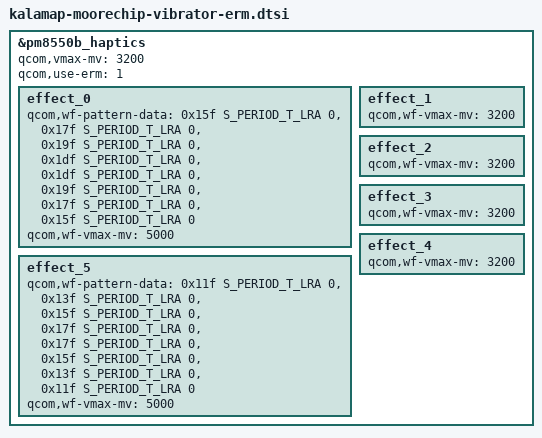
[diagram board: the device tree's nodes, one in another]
&pm8550b_haptics {
	status = "okay";
	qcom,vmax-mv = <3200>;
	qcom,use-erm = <1>;

	effect_0 {
		/* CLICK */
		qcom,wf-pattern-data =  <0x15f  S_PERIOD_T_LRA  0>,
					<0x17f  S_PERIOD_T_LRA  0>,
					<0x19f  S_PERIOD_T_LRA  0>,
					<0x1df  S_PERIOD_T_LRA  0>,
					<0x1df  S_PERIOD_T_LRA  0>,
					<0x19f  S_PERIOD_T_LRA  0>,
					<0x17f  S_PERIOD_T_LRA  0>,
					<0x15f  S_PERIOD_T_LRA  0>;
		/delete-property/ qcom,wf-pattern-preload;
		qcom,wf-vmax-mv = <5000>;
	};

	effect_1 {
		/* DOUBLE_CLICK */
		qcom,wf-vmax-mv = <3200>;
	};

	effect_2 {
		/* TICK */
		qcom,wf-vmax-mv = <3200>;
	};

	effect_3 {
		/* THUD */
		qcom,wf-vmax-mv = <3200>;
	};

	effect_4 {
		/* POP */
		qcom,wf-vmax-mv = <3200>;
	};

	effect_5 {
		/* HEAVY CLICK */
		qcom,wf-pattern-data =  <0x11f  S_PERIOD_T_LRA  0>,
					<0x13f  S_PERIOD_T_LRA  0>,
					<0x15f  S_PERIOD_T_LRA  0>,
					<0x17f  S_PERIOD_T_LRA  0>,
					<0x17f  S_PERIOD_T_LRA  0>,
					<0x15f  S_PERIOD_T_LRA  0>,
					<0x13f  S_PERIOD_T_LRA  0>,
					<0x11f  S_PERIOD_T_LRA  0>;
		qcom,wf-vmax-mv = <5000>;
	};
};
